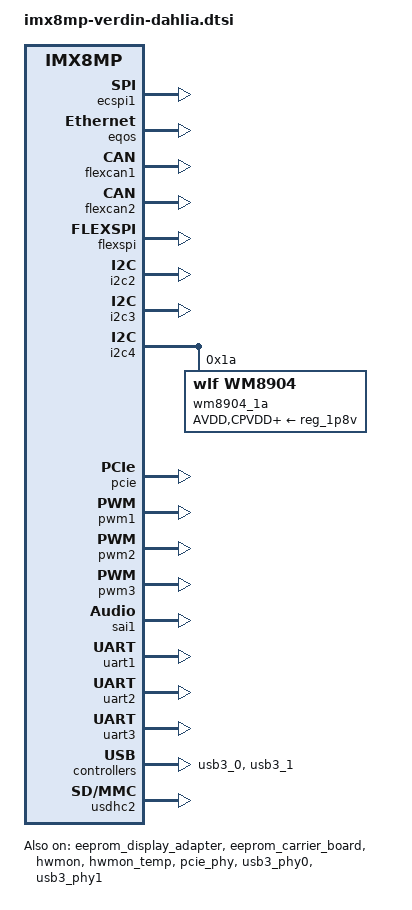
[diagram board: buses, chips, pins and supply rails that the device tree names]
/ {
	sound {
		compatible = "simple-audio-card";
		simple-audio-card,bitclock-master = <&codec_dai>;
		simple-audio-card,format = "i2s";
		simple-audio-card,frame-master = <&codec_dai>;
		simple-audio-card,mclk-fs = <256>;
		simple-audio-card,name = "imx8mp-wm8904";
		simple-audio-card,routing =
			"Headphone Jack", "HPOUTL",
			"Headphone Jack", "HPOUTR",
			"IN2L", "Line In Jack",
			"IN2R", "Line In Jack",
			"Headphone Jack", "MICBIAS",
			"IN1L", "Headphone Jack";
		simple-audio-card,widgets =
			"Microphone", "Headphone Jack",
			"Headphone", "Headphone Jack",
			"Line", "Line In Jack";
		codec_dai: simple-audio-card,codec {
			clocks = <&audio_blk_ctrl IMX8MP_CLK_AUDIOMIX_SAI1_MCLK1>;
			sound-dai = <&wm8904_1a>;
		};
		simple-audio-card,cpu {
			sound-dai = <&sai1>;
		};
	};
};
&backlight {
	power-supply = <&reg_3p3v>;
};
&ecspi1 {
	status = "okay";
};
&eeprom_display_adapter {
	status = "okay";
};
&eeprom_carrier_board {
	status = "okay";
};
&eqos {
	status = "okay";
};
&flexcan1 {
	status = "okay";
};
&flexcan2 {
	status = "okay";
};
&flexspi {
	status = "okay";
};
&hwmon {
	status = "okay";
};
&hwmon_temp {
	vs-supply = <&reg_1p8v>;
	status = "okay";
};
&i2c2 {
	status = "okay";
};
&i2c3 {
	status = "okay";
};
&i2c4 {
	status = "okay";
	wm8904_1a: audio-codec@1a {
		compatible = "wlf,wm8904";
		reg = <0x1a>;
		pinctrl-names = "default";
		pinctrl-0 = <&pinctrl_sai1>;
		#sound-dai-cells = <0>;
		clocks = <&audio_blk_ctrl IMX8MP_CLK_AUDIOMIX_SAI1_MCLK1>;
		clock-names = "mclk";
		AVDD-supply = <&reg_1p8v>;
		CPVDD-supply = <&reg_1p8v>;
		DBVDD-supply = <&reg_1p8v>;
		DCVDD-supply = <&reg_1p8v>;
		MICVDD-supply = <&reg_1p8v>;
	};
};
&pcie {
	status = "okay";
};
&pcie_phy {
	status = "okay";
};
&pwm1 {
	status = "okay";
};
&pwm2 {
	status = "okay";
};
&pwm3 {
	status = "okay";
};
&reg_usdhc2_vmmc {
	vin-supply = <&reg_3p3v>;
};
&sai1 {
	assigned-clocks = <&clk IMX8MP_CLK_SAI1>;
	assigned-clock-parents = <&clk IMX8MP_AUDIO_PLL1_OUT>;
	assigned-clock-rates = <24576000>;
	fsl,sai-mclk-direction-output;
	status = "okay";
};
&uart1 {
	status = "okay";
};
&uart2 {
	status = "okay";
};
&uart3 {
	status = "okay";
};
&usb3_0 {
	status = "okay";
};
&usb3_phy0 {
	status = "okay";
};
&usb3_1 {
	fsl,permanently-attached;
	status = "okay";
};
&usb3_phy1 {
	status = "okay";
};
&usdhc2 {
	status = "okay";
};
